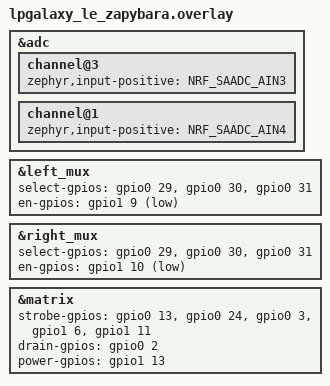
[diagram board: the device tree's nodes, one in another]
/*
 * Copyright (c) 2020 The ZMK Contributors
 *
 * SPDX-License-Identifier: MIT
 */

#include <zephyr/dt-bindings/dt-util.h>
#include <zephyr/dt-bindings/adc/adc.h>
#include <zephyr/dt-bindings/gpio/nordic-nrf-gpio.h>

#include <freq.h>
#include "lpgalaxy_le_zapybara.dts"

&adc {
    // Battery Sensing
    channel@3 {
        zephyr,input-positive = <NRF_SAADC_AIN3>; /* P0.05 */
    };

    // EC Read
    channel@1 {
        zephyr,input-positive = <NRF_SAADC_AIN4>; /* P0.28 */
    };
};

/* mux enable and selection pins */
&left_mux {
    select-gpios
        = <&gpio0 29 GPIO_ACTIVE_HIGH>
        , <&gpio0 30  GPIO_ACTIVE_HIGH>
        , <&gpio0 31 GPIO_ACTIVE_HIGH>
        ;
    en-gpios = <&gpio1 9 GPIO_ACTIVE_LOW>;
};

&right_mux {
    select-gpios
        = <&gpio0 29 GPIO_ACTIVE_HIGH>
        , <&gpio0 30  GPIO_ACTIVE_HIGH>
        , <&gpio0 31 GPIO_ACTIVE_HIGH>
        ;
    en-gpios = <&gpio1 10 GPIO_ACTIVE_LOW>;
};

/* kscan? row gpios 5 rows */

&matrix {
    strobe-gpios
    = <&gpio0 13  (GPIO_ACTIVE_HIGH| NRF_GPIO_DRIVE_H0H1)>
    , <&gpio0 24 (GPIO_ACTIVE_HIGH| NRF_GPIO_DRIVE_H0H1)>
    , <&gpio0 3  (GPIO_ACTIVE_HIGH| NRF_GPIO_DRIVE_H0H1)>
    , <&gpio1 6  (GPIO_ACTIVE_HIGH| NRF_GPIO_DRIVE_H0H1)>
    , <&gpio1 11  (GPIO_ACTIVE_HIGH| NRF_GPIO_DRIVE_H0H1)>
    ;
    drain-gpios = <&gpio0 2 (GPIO_ACTIVE_HIGH | NRF_GPIO_DRIVE_H0H1)>;
    power-gpios = <&gpio1 13 (GPIO_ACTIVE_HIGH | NRF_GPIO_DRIVE_H0H1)>;
};

/*
 * maybe accelerometer related, adxl362 accelerometer initialization
 * &spi1_default {
 *   group1 {
 *       psels = <NRF_PSEL(SPIM_MOSI, 1, 9)>,
 *           <NRF_PSEL(SPIM_MISO, 0, 5)>,
 *           <NRF_PSEL(SPIM_SCK, 0, 8)>;
 *   };
 * };
 */

/* &spi1_sleep {
 *   group1 {
 *       psels = <NRF_PSEL(SPIM_MOSI, 1, 9)>,
 *           <NRF_PSEL(SPIM_MISO, 0, 5)>,
 *           <NRF_PSEL(SPIM_SCK, 0, 8)>;
 *       low-power-enable;
 *   };
 * };
 */

/*
 * &spi1 {
 *   cs-gpios = <&gpio0 6 GPIO_ACTIVE_LOW>;
 * };
 */

/*
 * &wakeup_trigger {
 *   int2-gpios = <&gpio1 4 (GPIO_ACTIVE_HIGH)>;
 * };
 */
